# STM32WL54CCU6@M0 register map
File version: 1.0
Registers are 32-bit, access not given, reset 0x0 unless marked. A register's access mark holds for its fields unless they carry their own. Offsets are from the block's base; [hi:lo] are bit positions; {n}, {i} and the like mark numbered series; 'fields as' and 'values as' point back to an identical list.

## GPIO
Base 0x48001C00
0x1C00 MODER
  [7:6] MODE3
0x1C04 OTYPER
  [3] OT3
0x1C08 OSPEEDR
  [7:6] OSPEED3
0x1C0C PUPDR
  [7:6] PUPD3
0x1C10 IDR
  [3] ID3
0x1C14 ODR
  [3] OD3
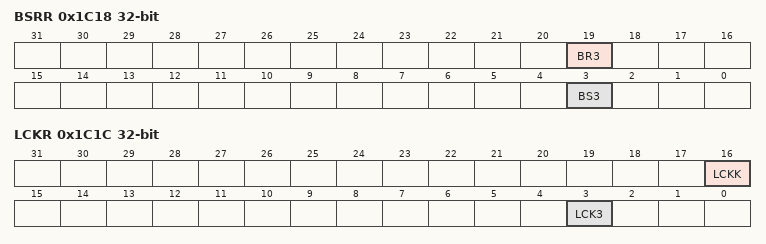
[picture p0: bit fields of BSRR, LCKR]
0x1C18 BSRR
  [19] BR3, [3] BS3
0x1C1C LCKR
  [16] LCKK, [3] LCK3
0x1C20 AFRL
  [15:12] AFSEL3
0x1C28 BRR
  [3] BR3

## PWR
Base 0x58000400
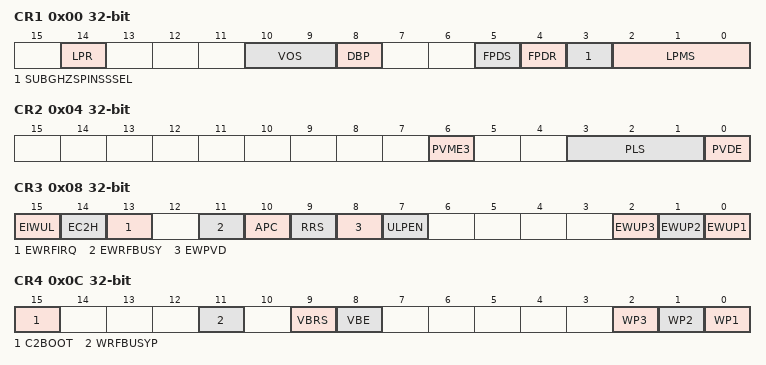
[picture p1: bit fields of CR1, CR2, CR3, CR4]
0x00 CR1
  [14] LPR, [10:9] VOS, [8] DBP, [5] FPDS, [4] FPDR, [3] SUBGHZSPINSSSEL, [2:0] LPMS
0x04 CR2
  [6] PVME3, [3:1] PLS, [0] PVDE
0x08 CR3
  [15] EIWUL, [14] EC2H, [13] EWRFIRQ, [11] EWRFBUSY, [10] APC, [9] RRS, [8] EWPVD, [7] ULPEN, [2] EWUP3, [1] EWUP2, [0] EWUP1
0x0C CR4
  [15] C2BOOT, [11] WRFBUSYP, [9] VBRS, [8] VBE, [2] WP3, [1] WP2, [0] WP1
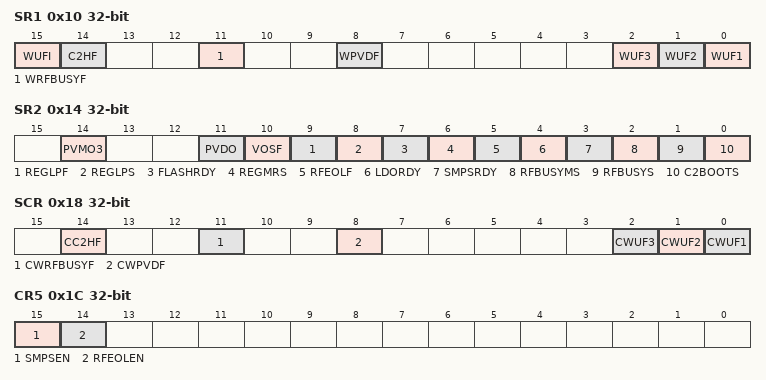
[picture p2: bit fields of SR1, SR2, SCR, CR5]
0x10 SR1
  [15] WUFI, [14] C2HF, [11] WRFBUSYF, [8] WPVDF, [2] WUF3, [1] WUF2, [0] WUF1
0x14 SR2
  [14] PVMO3, [11] PVDO, [10] VOSF, [9] REGLPF, [8] REGLPS, [7] FLASHRDY, [6] REGMRS, [5] RFEOLF, [4] LDORDY, [3] SMPSRDY, [2] RFBUSYMS, [1] RFBUSYS, [0] C2BOOTS
0x18 SCR
  [14] CC2HF, [11] CWRFBUSYF, [8] CWPVDF, [2] CWUF3, [1] CWUF2, [0] CWUF1
0x1C CR5
  [15] SMPSEN, [14] RFEOLEN
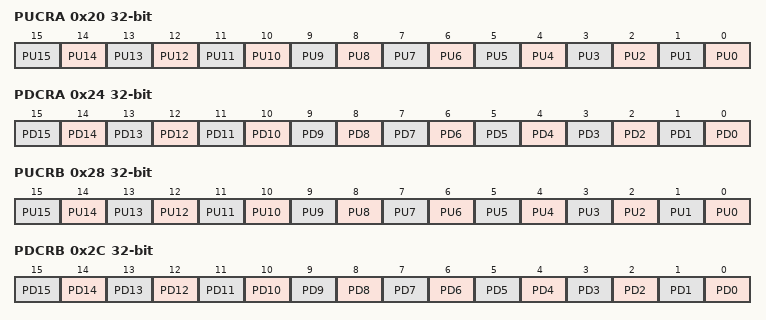
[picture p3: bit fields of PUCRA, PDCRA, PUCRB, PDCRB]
0x20 PUCRA
  [n] PU{n} (n=0..15)
0x24 PDCRA
  [n] PD{n} (n=0..15)
0x28 PUCRB
  [n] PU{n} (n=0..15)
0x2C PDCRB
  [n] PD{n} (n=0..15)
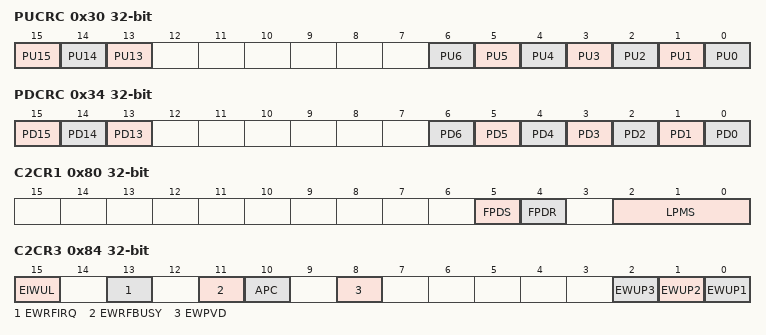
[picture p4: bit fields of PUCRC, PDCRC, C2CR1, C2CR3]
0x30 PUCRC
  [15] PU15, [14] PU14, [13] PU13, [n] PU{n} (n=0..6)
0x34 PDCRC
  [15] PD15, [14] PD14, [13] PD13, [n] PD{n} (n=0..6)
0x58 PUCRH
  [3] PU3
0x5C PDCRH
  [3] PD3
0x80 C2CR1
  [5] FPDS, [4] FPDR, [2:0] LPMS
0x84 C2CR3
  [15] EIWUL, [13] EWRFIRQ, [11] EWRFBUSY, [10] APC, [8] EWPVD, [2] EWUP3, [1] EWUP2, [0] EWUP1
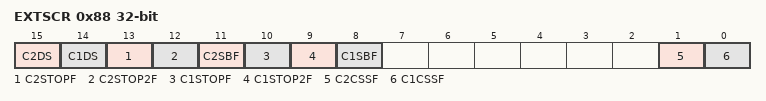
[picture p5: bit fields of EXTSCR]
0x88 EXTSCR
  [15] C2DS, [14] C1DS, [13] C2STOPF, [12] C2STOP2F, [11] C2SBF, [10] C1STOPF, [9] C1STOP2F, [8] C1SBF, [1] C2CSSF, [0] C1CSSF
0x8C SECCFGR
  [15] C2EWILA
0x90 SUBGHZSPICR
  [15] NSS
0x98 RSSCMDR
  [7:0] RSSCMD

## EXTI
Base 0x58000800
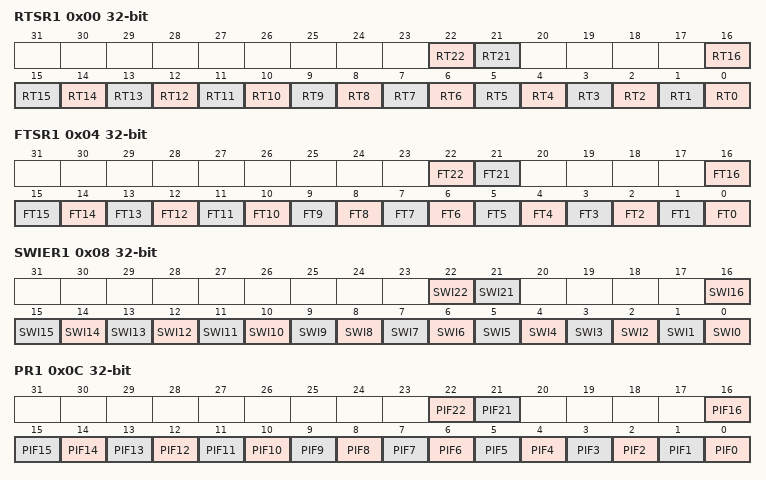
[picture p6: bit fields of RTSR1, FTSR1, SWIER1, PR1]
0x00 RTSR1
  [22] RT22, [21] RT21, [n] RT{n} (n=0..16)
0x04 FTSR1
  [22] FT22, [21] FT21, [n] FT{n} (n=0..16)
0x08 SWIER1
  [22] SWI22, [21] SWI21, [n] SWI{n} (n=0..16)
0x0C PR1
  [22] PIF22, [21] PIF21, [n] PIF{n} (n=0..16)
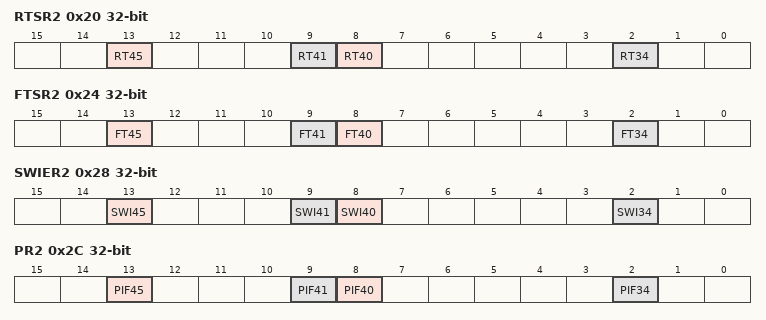
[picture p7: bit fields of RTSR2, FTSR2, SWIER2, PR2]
0x20 RTSR2
  [13] RT45, [9] RT41, [8] RT40, [2] RT34
0x24 FTSR2
  [13] FT45, [9] FT41, [8] FT40, [2] FT34
0x28 SWIER2
  [13] SWI45, [9] SWI41, [8] SWI40, [2] SWI34
0x2C PR2
  [13] PIF45, [9] PIF41, [8] PIF40, [2] PIF34
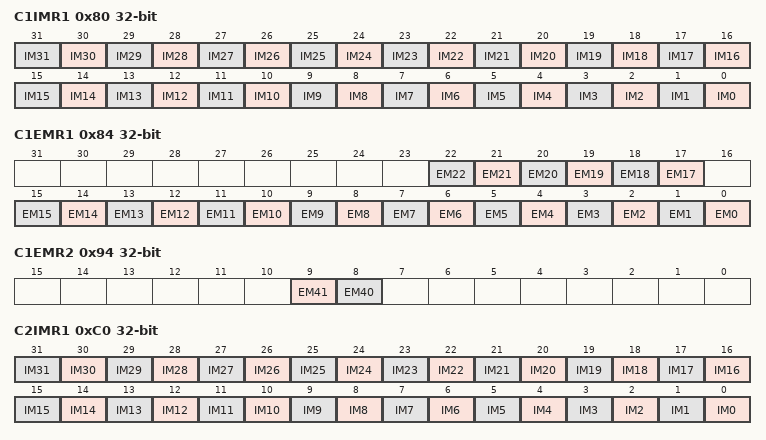
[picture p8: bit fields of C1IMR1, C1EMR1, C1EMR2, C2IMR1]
0x80 C1IMR1
  [n] IM{n} (n=0..31)
0x84 C1EMR1
  [n] EM{n} (n=17..22), [n] EM{n} (n=0..15)
0x90 C1IMR2
  [13] IM45, [12] IM44, [14:11] IM46, [n-32] IM{n} (n=36..42), [2] IM34
0x94 C1EMR2
  [9] EM41, [8] EM40
0xC0 C2IMR1
  [n] IM{n} (n=0..31)
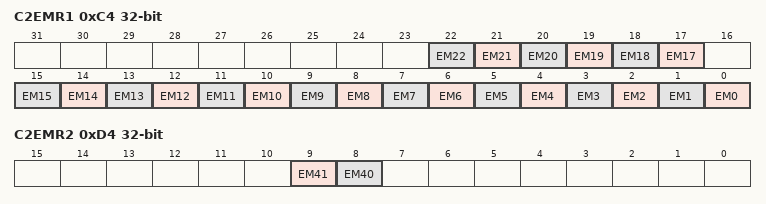
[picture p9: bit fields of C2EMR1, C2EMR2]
0xC4 C2EMR1
  [n] EM{n} (n=17..22), [n] EM{n} (n=0..15)
0xD0 C2IMR2
  fields as C1IMR2
0xD4 C2EMR2
  [9] EM41, [8] EM40

## IPCC
Base 0x58000C00
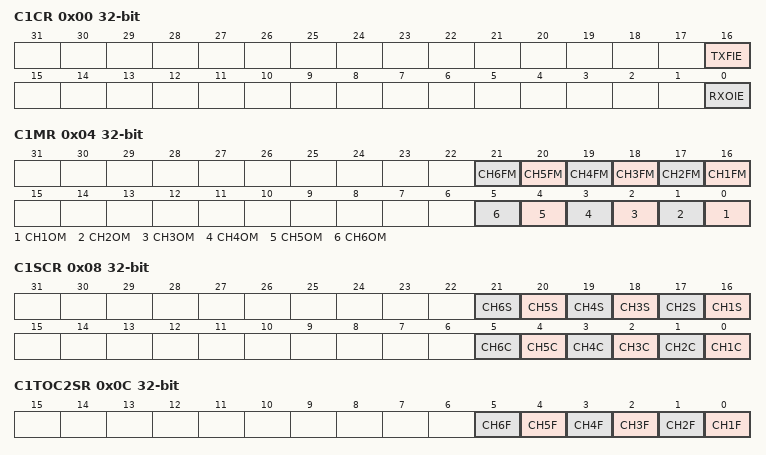
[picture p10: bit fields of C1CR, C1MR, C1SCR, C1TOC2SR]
0x00 C1CR
  [16] TXFIE, [0] RXOIE
0x04 C1MR
  [n+15] CH{n}FM (n=1..6), [n-1] CH{n}OM (n=1..6)
0x08 C1SCR
  [n+15] CH{n}S (n=1..6), [n-1] CH{n}C (n=1..6)
0x0C C1TOC2SR
  [n-1] CH{n}F (n=1..6)
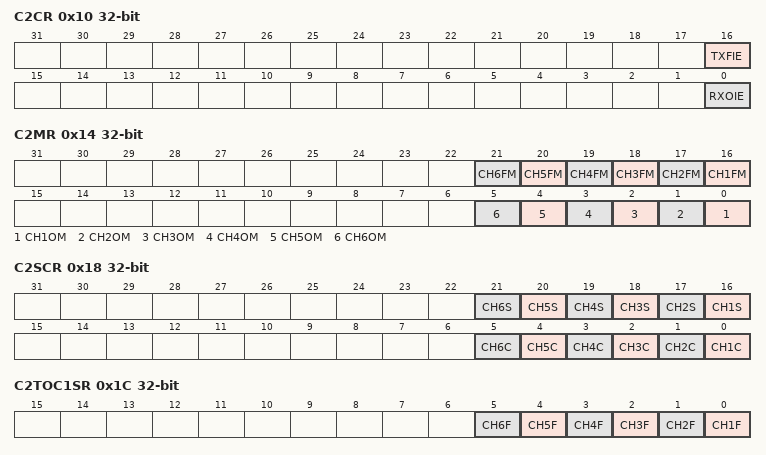
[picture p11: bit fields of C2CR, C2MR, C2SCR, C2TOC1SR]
0x10 C2CR
  [16] TXFIE, [0] RXOIE
0x14 C2MR
  [n+15] CH{n}FM (n=1..6), [n-1] CH{n}OM (n=1..6)
0x18 C2SCR
  [n+15] CH{n}S (n=1..6), [n-1] CH{n}C (n=1..6)
0x1C C2TOC1SR
  [n-1] CH{n}F (n=1..6)

## TRNG
Base 0x58001000
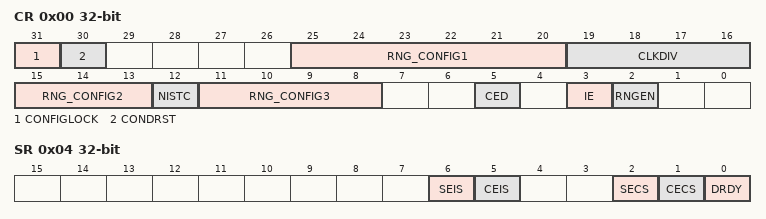
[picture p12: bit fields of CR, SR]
0x00 CR
  [31] CONFIGLOCK, [30] CONDRST, [25:20] RNG_CONFIG1, [19:16] CLKDIV, [15:13] RNG_CONFIG2, [12] NISTC, [11:8] RNG_CONFIG3, [5] CED, [3] IE, [2] RNGEN
0x04 SR
  [6] SEIS, [5] CEIS, [2] SECS, [1] CECS, [0] DRDY
0x08 DR
  [31:0] RNDATA
0x10 HTCR
  [31:0] HTCFG

## HSEM
Base 0x58001400
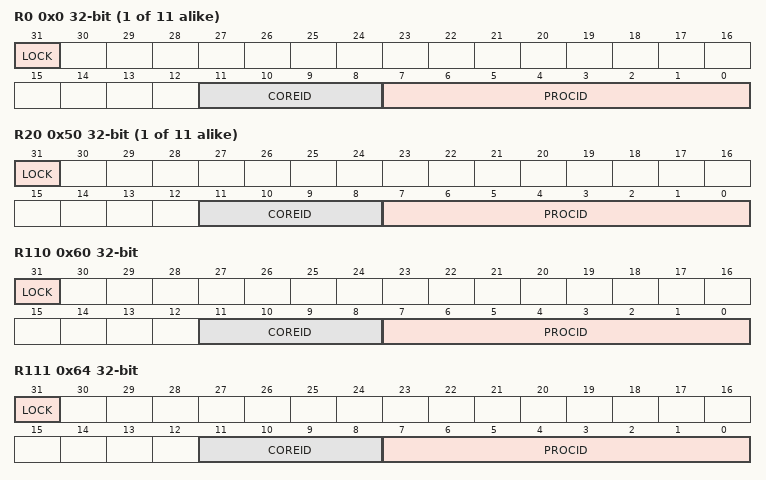
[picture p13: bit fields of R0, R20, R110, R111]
{0x0+4i} R{i} (i=0..10)
  [31] LOCK, [11:8] COREID, [7:0] PROCID
{0x0+4i} R{i} (i=20..30)
  [31] LOCK, [11:8] COREID, [7:0] PROCID
0x60 R110
  [31] LOCK, [11:8] COREID, [7:0] PROCID
0x64 R111
  [31] LOCK, [11:8] COREID, [7:0] PROCID
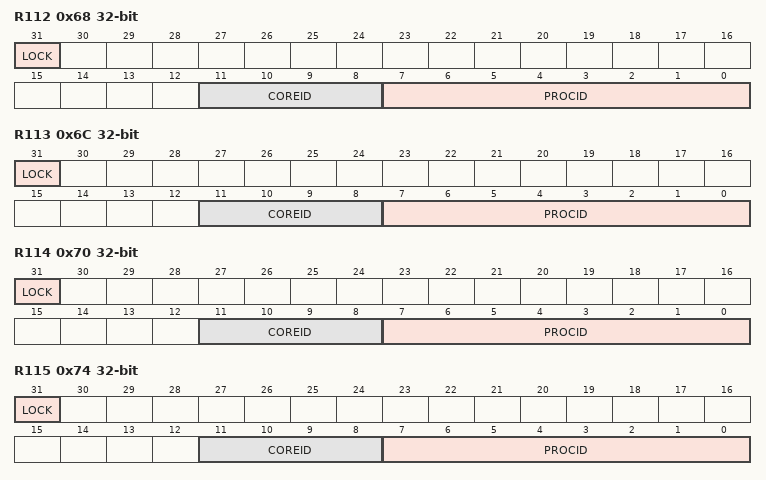
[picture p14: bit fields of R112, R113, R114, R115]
0x68 R112
  [31] LOCK, [11:8] COREID, [7:0] PROCID
0x6C R113
  [31] LOCK, [11:8] COREID, [7:0] PROCID
0x70 R114
  [31] LOCK, [11:8] COREID, [7:0] PROCID
0x74 R115
  [31] LOCK, [11:8] COREID, [7:0] PROCID
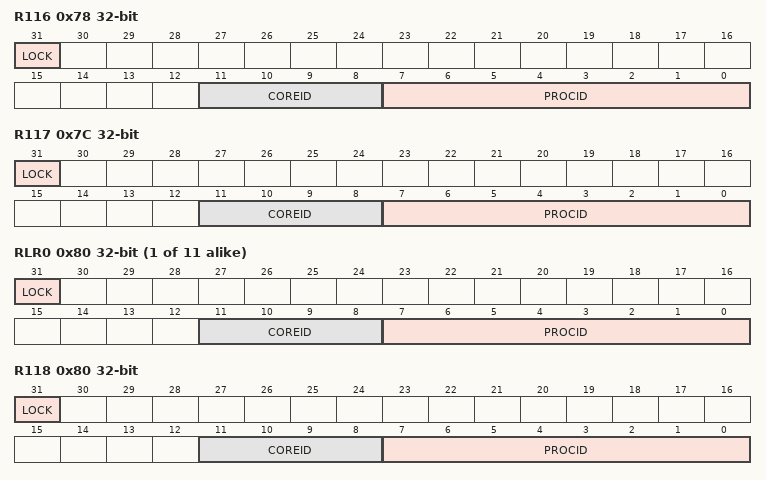
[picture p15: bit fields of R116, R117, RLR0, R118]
0x78 R116
  [31] LOCK, [11:8] COREID, [7:0] PROCID
0x7C R117
  [31] LOCK, [11:8] COREID, [7:0] PROCID
{0x80+4i} RLR{i} (i=0..10)
  [31] LOCK, [11:8] COREID, [7:0] PROCID
0x80 R118
  [31] LOCK, [11:8] COREID, [7:0] PROCID
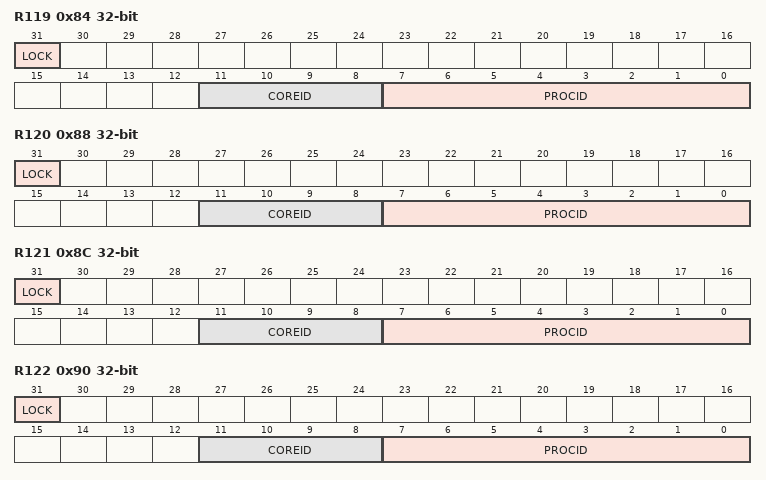
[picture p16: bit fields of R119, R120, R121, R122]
0x84 R119
  [31] LOCK, [11:8] COREID, [7:0] PROCID
0x88 R120
  [31] LOCK, [11:8] COREID, [7:0] PROCID
0x8C R121
  [31] LOCK, [11:8] COREID, [7:0] PROCID
0x90 R122
  [31] LOCK, [11:8] COREID, [7:0] PROCID
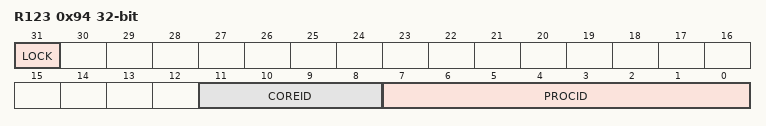
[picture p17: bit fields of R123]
0x94 R123
  [31] LOCK, [11:8] COREID, [7:0] PROCID
0x98 R124
  [31] LOCK, [11:8] COREID, [7:0] PROCID
0x9C R125
  [31] LOCK, [11:8] COREID, [7:0] PROCID
0xA0 R126
  [31] LOCK, [11:8] COREID, [7:0] PROCID
0xA4 R127
  [31] LOCK, [11:8] COREID, [7:0] PROCID
0xA8 R128
  [31] LOCK, [11:8] COREID, [7:0] PROCID
0xAC R129
  [31] LOCK, [11:8] COREID, [7:0] PROCID
0xB0 R130
  [31] LOCK, [11:8] COREID, [7:0] PROCID
{0x80+4i} RLR{i} (i=20..30)
  [31] LOCK, [11:8] COREID, [7:0] PROCID
0xE0 RLR110
  [31] LOCK, [11:8] COREID, [7:0] PROCID
0xE4 RLR111
  [31] LOCK, [11:8] COREID, [7:0] PROCID
0xE8 RLR112
  [31] LOCK, [11:8] COREID, [7:0] PROCID
0xEC RLR113
  [31] LOCK, [11:8] COREID, [7:0] PROCID
0xF0 RLR114
  [31] LOCK, [11:8] COREID, [7:0] PROCID
0xF4 RLR115
  [31] LOCK, [11:8] COREID, [7:0] PROCID
0xF8 RLR116
  [31] LOCK, [11:8] COREID, [7:0] PROCID
0xFC RLR117
  [31] LOCK, [11:8] COREID, [7:0] PROCID
0x100 C1IER
  [15:0] ISE
0x100 RLR118
  [31] LOCK, [11:8] COREID, [7:0] PROCID
0x104 C1ICR
  [15:0] ISC
0x104 RLR119
  [31] LOCK, [11:8] COREID, [7:0] PROCID
0x108 C1ISR
  [15:0] ISF
0x108 RLR120
  [31] LOCK, [11:8] COREID, [7:0] PROCID
0x10C C1MISR
  [15:0] MISF
0x10C RLR121
  [31] LOCK, [11:8] COREID, [7:0] PROCID
0x110 C2IER
  [15:0] ISE
0x110 RLR122
  [31] LOCK, [11:8] COREID, [7:0] PROCID
0x114 C2ICR
  [15:0] ISC
0x114 RLR123
  [31] LOCK, [11:8] COREID, [7:0] PROCID
0x118 C2ISR
  [15:0] ISF
0x118 RLR124
  [31] LOCK, [11:8] COREID, [7:0] PROCID
0x11C C2MISR
  [15:0] MISF
0x11C RLR125
  [31] LOCK, [11:8] COREID, [7:0] PROCID
0x120 RLR126
  [31] LOCK, [11:8] COREID, [7:0] PROCID
0x124 RLR127
  [31] LOCK, [11:8] COREID, [7:0] PROCID
0x128 RLR128
  [31] LOCK, [11:8] COREID, [7:0] PROCID
0x12C RLR129
  [31] LOCK, [11:8] COREID, [7:0] PROCID
0x130 RLR130
  [31] LOCK, [11:8] COREID, [7:0] PROCID
0x140 CR
  [31:16] KEY, [11:8] COREID
0x144 KEYR
  [31:16] KEY

## AES
Base 0x58001800
0x00 CR
  [23:20] NPBLB, [18] KEYSIZE, [14:13] GCMPH, [12] DMAOUTEN, [11] DMAINEN, [10] ERRIE, [9] CCFIE, [8] ERRC, [7] CCFC, [16:5] CHMOD, [4:3] MODE, [2:1] DATATYPE, [0] EN
0x04 SR
  [3] BUSY, [2] WRERR, [1] RDERR, [0] CCF
0x08 DINR
  [31:0] DIN
0x0C DOUTR
  [31:0] DOUT
{0x10+4i} KEYR{i} (i=0..3)
  [31:0] KEY
{0x20+4i} IVR{i} (i=0..3)
  [31:0] IVI
{0x20+4i} KEYR{i} (i=4..7)
  [31:0] KEY
{0x40+4i} SUSP{i}R (i=0..7)
  [31:0] SUSP

## PKA
Base 0x58002000
Same registers: PKARAM 0x58002400, PKARAM 0x58002400, PKA 0x58003400, PKA 0x58003400
0x00 CR
  [20] ADDRERRIE, [19] RAMERRIE, [17] PROCENDIE, [13:8] MODE, [1] START, [0] EN
0x04 SR
  [20] ADDRERRF, [19] RAMERRF, [17] PROCENDF, [16] BUSY
0x08 CLRFR
  [20] ADDRERRFC, [19] RAMERRFC, [17] PROCENDFC

## GTZC_TZSC
Base 0x58004400
Same registers: GTZC_TZIC 0x58004800
0x00 TZSC_CR
  [0] LCK
0x10 TZSC_SECCFGR1
  [13] PKASEC, [3] RNGSEC, [2] AESSEC
0x20 TZSC_PRIVCFGR1
  [13] PKAPRIV, [4] SUBGHZSPIPRIV, [3] RNGPRIV, [2] AESPRIV
{0x128+8i} TZSC_MPCWM{i}_UPWMR (i=1..3)
  [27:16] LGTH
0x134 TZSC_MPCWM1_UPWWMR
  [27:16] LGTH

## SUBGHZSPI
Base 0x58010000
0x6AC GBSYNCR
  [6] SBITSYNCEN, [5] RXDINV, [4] BITSYNCDIS
0x6B8 GPKTCTL1AR
  [5] SYNCDETEN, [4] CONTTX, [3:2] INFSQEQSEL, [1] INFSSQEQEN, [0] WHITEINI
0x6B9 GWHITEINIRL
  [7:0] WHITEINI
0x6BC GCRCINIRH
  [7:0] CRCINI
0x6BD GCRCINIRL
  [7:0] CRCINI
0x6BE GCRCPOLRH
  [7:0] CRCPOL
0x6BF GCRCPOLRL
  [7:0] CRCPOL
{0x6C0+i} GSYNCR{i} (i=0..7)
  [7:0] SYNCWORD
0x740 LSYNCRH
  [7:0] SYNCWORD
0x741 LSYNCRL
  [7:0] SYNCWORD
0x819 RNGR3
  [7:0] RNDATA
0x81A RNGR2
  [7:0] RNDATA
0x81B RNGR1
  [7:0] RNDATA
0x81C RNGR0
  [7:0] RNDATA
0x89B AGCRSSIC0R
  [6] MODE, [5] MC, [4:2] LENGTH
0x8AC RXGAINCR
  [7:2] SENSI_ADJUST, [1:0] PMODE
0x8E7 PAOCPR
  [5:0] OCP
0x911 HSEINTRIMR
  [5:0] TRIM
0x912 HSEOUTTRIMR
  [5:0] TRIM
0x916 SMPSC0R
  [6] CLKDE
0x91A PCR
  [6] CLE, [5:4] CLV
0x91F REGDRVTSTR
  [3:1] TRIM, [0] EN
0x923 SMPSC2R
  [2:1] DRV
